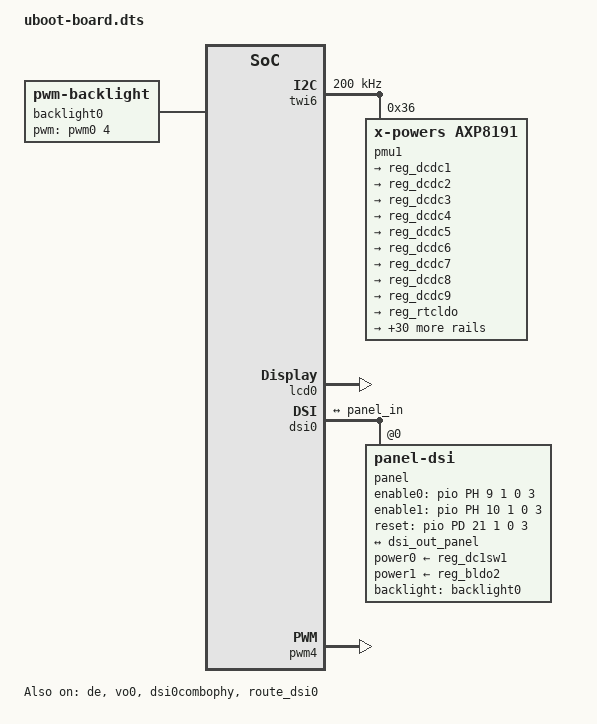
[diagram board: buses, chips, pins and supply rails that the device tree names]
/*
 * Allwinner Technology CO., Ltd. sun60iw2p1 soc board.
 *
 * soc board support.
 */

/ {
	backlight0: backlight0 {
		compatible = "pwm-backlight";
		status = "okay";
		brightness-levels = <
			  0   1   2   3   4   5   6   7
			  8   9  10  11  12  13  14  15
			 16  17  18  19  20  21  22  23
			 24  25  26  27  28  29  30  31
			 32  33  34  35  36  37  38  39
			 40  41  42  43  44  45  46  47
			 48  49  50  51  52  53  54  55
			 56  57  58  59  60  61  62  63
			 64  65  66  67  68  69  70  71
			 72  73  74  75  76  77  78  79
			 80  81  82  83  84  85  86  87
			 88  89  90  91  92  93  94  95
			 96  97  98  99 100 101 102 103
			104 105 106 107 108 109 110 111
			112 113 114 115 116 117 118 119
			120 121 122 123 124 125 126 127
			128 129 130 131 132 133 134 135
			136 137 138 139 140 141 142 143
			144 145 146 147 148 149 150 151
			152 153 154 155 156 157 158 159
			160 161 162 163 164 165 166 167
			168 169 170 171 172 173 174 175
			176 177 178 179 180 181 182 183
			184 185 186 187 188 189 190 191
			192 193 194 195 196 197 198 199
			200 201 202 203 204 205 206 207
			208 209 210 211 212 213 214 215
			216 217 218 219 220 221 222 223
			224 225 226 227 228 229 230 231
			232 233 234 235 236 237 238 239
			240 241 242 243 244 245 246 247
			248 249 250 251 252 253 254 255>;
		default-brightness-level = <73>;
		pwms = <&pwm0 4 25000 0>;
	};
};

&platform {
	eraseflag   = <1>;
	next_work   = <3>;
	debug_mode  = <4>;
};

&target {
	boot_clock = <1008>;	/*CPU boot frequency, Unit: MHz*/
	storage_type = <0xffffffff>; /*boot medium, 0-nand, 1-card0, 2-card2, -1(defualt)auto scan*/
	burn_key = <1>;		/*1:support burn key; 0:not support burn key*/
	dragonboard_test = <0>;	/*1:support card boot dragonboard; 0:not support card boot dragonboard*/
};

&power_sply {
	ntc_status = <0>;
};

&charger0 {
	pmu_safe_vol = <3400>;
	ntc_cur = <60>;
	safe_temp_H = <600>;//60
	safe_temp_L = <0xFFFFFFCE>;//-5
	pmu_bat_temp_para1 = <4541>; //Murata -25
	pmu_bat_temp_para2 = <2762>; //-15
	pmu_bat_temp_para3 = <2180>; //-10
	pmu_bat_temp_para4 = <1732>; //-5
	pmu_bat_temp_para5 = <1386>;//0
	pmu_bat_temp_para6 = <1117>; //5
	pmu_bat_temp_para7 = <905>; //10
	pmu_bat_temp_para8 = <606>; //20
	pmu_bat_temp_para9 = <414>; //30
	pmu_bat_temp_para10 = <290>; //40
	pmu_bat_temp_para11 = <244>; //45
	pmu_bat_temp_para12 = <205>; //50
	pmu_bat_temp_para13 = <176>; //55
	pmu_bat_temp_para14 = <150>; //60
	pmu_bat_temp_para15 = <111>; //70
	pmu_bat_temp_para16 = <83>; //80
};

&twi6 {
	clock-frequency = <200000>;
	pinctrl-0 = <&s_twi0_pins_a>;
	pinctrl-1 = <&s_twi0_pins_b>;
	twi-supply = <&reg_aldo3>;
	status = "okay";

	pmu1: pmu@36 {
		compatible = "x-powers,axp8191";
		reg = <0x36>;
		status = "okay";
		regulator0: regulators@0 {
			reg_dcdc1: dcdc1 {
				regulator-name = "axp8191-dcdc1";
			};
			reg_dcdc2: dcdc2 {
				regulator-name = "axp8191-dcdc2";
			};
			reg_dcdc3: dcdc3 {
				regulator-name = "axp8191-dcdc3";
			};
			reg_dcdc4: dcdc4 {
				regulator-name = "axp8191-dcdc4";
			};
			reg_dcdc5: dcdc5 {
				regulator-name = "axp8191-dcdc5";
			};
			reg_dcdc6: dcdc6 {
				regulator-name = "axp8191-dcdc6";
			};
			reg_dcdc7: dcdc7 {
				regulator-name = "axp8191-dcdc7";
			};
			reg_dcdc8: dcdc8 {
				regulator-name = "axp8191-dcdc8";
			};
			reg_dcdc9: dcdc9 {
				regulator-name = "axp8191-dcdc9";
			};
			reg_rtcldo: rtcldo {
				regulator-name = "axp8191-rtcldo";
			};
			reg_aldo1: aldo1 {
				regulator-name = "axp8191-aldo1";
			};
			reg_aldo2: aldo2 {
				regulator-name = "axp8191-aldo2";
			};
			reg_aldo3: aldo3 {
				regulator-name = "axp8191-aldo3";
			};
			reg_aldo4: aldo4 {
				regulator-name = "axp8191-aldo4";
			};
			reg_aldo5: aldo5 {
				regulator-name = "axp8191-aldo5";
			};
			reg_aldo6: aldo6 {
				regulator-name = "axp8191-aldo6";
			};
			reg_bldo1: bldo1 {
				regulator-name = "axp8191-bldo1";
			};
			reg_bldo2: bldo2 {
				regulator-name = "axp8191-bldo2";
			};
			reg_bldo3: bldo3 {
				regulator-name = "axp8191-bldo3";
			};
			reg_bldo4: bldo4 {
				regulator-name = "axp8191-bldo4";
			};
			reg_bldo5: bldo5 {
				regulator-name = "axp8191-bldo5";
			};
			reg_cldo1: cldo1 {
				regulator-name = "axp8191-cldo1";
			};
			reg_cldo2: cldo2 {
				regulator-name = "axp8191-cldo2";
			};
			reg_cldo3: cldo3 {
				regulator-name = "axp8191-cldo3";
			};
			reg_cldo4: cldo4 {
				regulator-name = "axp8191-cldo4";
			};
			reg_cldo5: cldo5 {
				regulator-name = "axp8191-cldo5";
			};
			reg_dldo1: dldo1 {
				regulator-name = "axp8191-dldo1";
			};
			reg_dldo2: dldo2 {
				regulator-name = "axp8191-dldo2";
			};
			reg_dldo3: dldo3 {
				regulator-name = "axp8191-dldo3";
			};
			reg_dldo4: dldo4 {
				regulator-name = "axp8191-dldo4";
			};
			reg_dldo5: dldo5 {
				regulator-name = "axp8191-dldo5";
			};
			reg_dldo6: dldo6 {
				regulator-name = "axp8191-dldo6";
			};
			reg_eldo1: eldo1 {
				regulator-name = "axp8191-eldo1";
			};
			reg_eldo2: eldo2 {
				regulator-name = "axp8191-eldo2";
			};
			reg_eldo3: eldo3 {
				regulator-name = "axp8191-eldo3";
			};
			reg_eldo4: eldo4 {
				regulator-name = "axp8191-eldo4";
			};
			reg_eldo5: eldo5 {
				regulator-name = "axp8191-eldo5";
			};
			reg_eldo6: eldo6 {
				regulator-name = "axp8191-eldo6";
			};
			reg_dc1sw1: dc1sw1 {
				regulator-name = "axp8191-dc1sw1";
				swin-supply = <&reg_dcdc1>;
			};
			reg_dc1sw2: dc1sw2 {
				regulator-name = "axp8191-dc1sw2";
				swin-supply = <&reg_dcdc1>;
			};
		};
	};
};

&sdc0_pins_a {
		allwinner,pins = "PF0", "PF1", "PF2",
				 "PF3", "PF4", "PF5";
		allwinner,function = "sdc0";
		allwinner,muxsel = <2>;
		allwinner,drive = <1>;
		allwinner,pull = <1>;
};

&sdc0_pins_b {
		allwinner,pins = "PF0", "PF1", "PF2",
				 "PF3", "PF4", "PF5";
		allwinner,function = "io_disabled";
		allwinner,muxsel = <7>;
		allwinner,drive = <0>;
		allwinner,pull = <1>;
};

&sdc0_pins_c {
		allwinner,pins = "PF0", "PF1", "PF2",
		  		 "PF3", "PF4", "PF5";
		allwinner,function = "uart0_jtag";
		allwinner,muxsel = <3>;
		allwinner,drive = <0>;
		allwinner,pull = <1>;
};


&sdc2_pins_a {
		allwinner,pins = "PC1", "PC5", "PC6",
				 "PC8", "PC9", "PC10", "PC11",
				 "PC13", "PC14", "PC15", "PC16";
		allwinner,function = "sdc2";
		allwinner,muxsel = <3>;
		allwinner,drive = <1>;
		allwinner,pull = <1>;
};

&sdc2_pins_b {
		allwinner,pins = "PC0", "PC1", "PC5", "PC6",
				 "PC8", "PC9", "PC10", "PC11",
				 "PC13", "PC14", "PC15", "PC16";
		allwinner,function = "io_disabled";
		allwinner,muxsel = <7>;
		allwinner,drive = <0>;
		allwinner,pull = <1>;
};

&sdc2_pins_c {
		allwinner,pins = "PC0";
		allwinner,function = "sdc2";
		allwinner,muxsel = <3>;
		allwinner,drive = <1>;
		allwinner,pull = <2>;
};

&pwm4_pin_active {
		allwinner,pins = "PD22";
		allwinner,function = "pwm0_4";
		allwinner,muxsel = <0x2>;
		allwinner,drive = <3>;
		allwinner,pull = <2>;
};

&pwm4_pin_sleep {
		allwinner,pins = "PD22";
		allwinner,function = "io_disabled";
		allwinner,muxsel = <0xf>;
		allwinner,drive = <3>;
		allwinner,pull = <2>;
};

&card0_boot_para {
		/* Avoid dtc compiling warnings. @TODO: Developer should modify this to the actual value */
		/* reg = <0x0 0x2 0x0 0x0>;  [> Avoid dtc compiling warnings. @TODO: Developer should modify this to the actual value <] */
	device_type = "card0_boot_para";
	card_ctrl = <0x0>;
	card_high_speed = <0x1>;
	card_line = <0x4>;
	clk_mmc = "sdmmc0_mod";
	pll-0 = "hosc";
	pll-1 = "pll_periph1_400m";
	pll-2 = "pll_periph1_300m";
	pinctrl-0 = <&sdc0_pins_a>;
	clk_type = "typ1";
};

&card2_boot_para {
	/*
	* Avoid dtc compiling warnings.
	* @TODO: Developer should modify this to the actual value
	*/
	reg = <0x0 0x3 0x0 0x0>;
	device_type = "card2_boot_para";
	card_ctrl = <0x2>;
	card_high_speed = <0x1>;
	card_line = <0x8>;
	clk_mmc = "sdmmc2_mod";
	pll-0 = "hosc";
	pll-1 = "pll_periph1_800m";
	pll-2 = "pll_periph1_600m";
	pinctrl-0 = <&sdc2_pins_a &sdc2_pins_c>;
	sdc_ex_dly_used = <0x2>;
	sdc_tm4_hs200_max_freq = <150>;
	sdc_tm4_hs400_max_freq = <150>;
	sdc_tm4_win_th = <0x7>;
	sdc_io_1v8 = <0x1>;
	sdc_type = "tm4";
	clk_type = "typ1";
};

&key_boot_recovery {
	device_type = "key_boot_recovery";
	recovery_key_used = <0x1>;
	press_mode_enable = <0x0>;
	key_work_mode = <0x2>;
	short_press_mode = <0x0>;
	long_press_mode = <0x1>;
	key_press_time = <0x7d0>;
	recovery_key = <&pio PB 1 0x0 0xffffffff 0xffffffff 0x1>;//vol+
};

&de {
	chn_cfg_mode = <0>;
	status = "okay";
};

&vo0 {
	status = "okay";
};

&lcd0 {
	status = "okay";
};

&dsi0 {
	status = "okay";
	pinctrl-0 = <&dsi0_4lane_pins_a>;
	pinctrl-1 = <&dsi0_4lane_pins_b>;
	pinctrl-names = "active","sleep";
	ports {
		dsi1_out: port@1{
			dsi_out_panel: endpoint {
				remote-endpoint = <&panel_in>;
			};
		};
        };
	panel: panel@0 {
		compatible = "panel-dsi";
		status = "okay";
		reg = <0>;
		power-delay-ms = <10>;
		power0-supply = <&reg_dc1sw1>;
		power1-supply = <&reg_bldo2>;

		enable0-gpios = <&pio PH 9 1 0 3 1>;
		enable1-gpios = <&pio PH 10 1 0 3 1>;
		reset-num = <2>;
		reset-delay-ms = <20>;
		reset-gpios = <&pio PD 21 1 0 3 1>;
		backlight = <&backlight0>;
		dsi,flags = <MIPI_DSI_MODE_VIDEO>;
		dsi,lanes = <4>;
		dsi,format = <0>;
		panel-init-sequence = [
			15 00 02 00 00
			15 00 02 FA 5A
			15 00 02 00 00
			39 00 04 FF 82 05 01
			15 00 02 00 80
			39 00 03 FF 82 05
			15 00 02 00 93
			15 00 02 C5 6B
			15 00 02 00 97
			15 00 02 C5 6B
			15 00 02 00 9E
			15 00 02 C5 0A
			15 00 02 00 9A
			15 00 02 C5 CD
			15 00 02 00 9C
			15 00 02 C5 CD
			15 00 02 00 B6
			39 00 03 C5 57 57
			15 00 02 00 B8
			39 00 03 C5 43 43
			15 00 02 00 A0
			15 00 02 A5 04
			15 00 02 00 00
			39 00 03 D8 B4 B4
			15 00 02 00 82
			15 00 02 C5 95
			15 00 02 00 83
			15 00 02 C5 07
			15 00 02 00 D9
			15 00 02 CB 40
			15 00 02 00 00
			39 00 11 E1 00 04 11 1E 27 31 41 4F 52 5F 63 79 88 73 71 65
			15 00 02 00 10
			39 00 09 E1 5B 4F 3E 34 2B 1E 16 15
			15 00 02 00 00
			39 00 11 E2  00 04 11 1E 27 31 41 4F 52 5F 63 79 88 73 71 65
			15 00 02 00 10
			39 00 09 E2 5B 4F 3E 34 2B 1B 0C 0A
			15 00 02 00 A1
			39 00 03 B3 04 B0
			15 00 02 00 A3
			39 00 03 B3 07 D0
			15 00 02 00 A5
			39 00 03 B3 80 13
			15 00 02 00 80
			39 00 08 CB 3C 3C 3C 3C 3C 3C 3C
			15 00 02 00 87
			15 00 02 CB 3C
			15 00 02 00 88
			39 00 09 CB 3C 3C 3C 3C 3C 3C 3C 3C
			15 00 02 00 90
			39 00 07 CB 03 3C 3C 3C 3C 3C
			15 00 02 00 97
			15 00 02 CB 33
			15 00 02 00 98
			39 00 09 CB 34 34 34 34 34 34 34 34
			15 00 02 00 A0
			39 00 09 CB 34 34 34 37 34 34 34 34
			15 00 02 00 A8
			39 00 07 CB C8 34 34 34 34 34
			15 00 02 00 B0
			39 00 08 CB 00 00 00 00 00 00 00
			15 00 02 00 B7
			15 00 02 CB 00
			15 00 02 00 B8
			39 00 09 CB 00 00 00 00 00 00 00 00
			15 00 02 00 C0
			39 00 08 CB 00 00 00 00 00 00 00
			15 00 02 00 C7
			15 00 02 CB 00
			15 00 02 00 80
			39 00 09 CC 2F 2F 2F 27 31 32 01 2C
			15 00 02 00 88
			39 00 09 CC 2D 1B 1D 1F 21 0B 0D 0F
			15 00 02 00 90
			39 00 07 CC 11 13 15 03 2F 2F
			15 00 02 00 80
			39 00 09 CD 2F 2F 2F 27 31 32 02 2C
			15 00 02 00 88
			39 00 09 CD 2D 1C 1E 20 22 0C 0E 10
			15 00 02 00 90
			39 00 07 CD 12 14 16 04 2F 2F
			15 00 02 00 80
			39 00 05 C2 8C 0A 7A AA
			15 00 02 00 84
			39 00 05 C2 8B 0A 7A AA
			15 00 02 00 C0
			39 00 08 C2 86 87 00 06 7A AA 0B
			15 00 02 00 C7
			39 00 08 C2 85 86 00 06 7A AA 0B
			15 00 02 00 D0
			39 00 08 C2 84 85 00 06 7A AA 0B
			15 00 02 00 D7
			39 00 08 C2 83 84 00 06 7A AA 0B
			15 00 02 00 E0
			39 00 08 C2 82 83 00 06 7A AA 0B
			15 00 02 00 E7
			39 00 08 C2 81 82 00 06 7A AA 0B
			15 00 02 00 F0
			39 00 08 C2 80 81 00 06 7A AA 0B
			15 00 02 00 F7
			39 00 08 C2 01 80 00 06 7A AA 0B
			15 00 02 00 80
			39 00 08 C3 02 8B 00 06 7A AA 0B
			15 00 02 00 87
			39 00 08 C3 03 8A 00 06 7A AA 0B
			15 00 02 00 90
			39 00 08 C3 04 89 00 06 7A AA 0B
			15 00 02 00 97
			39 00 08 C3 05 88 00 06 7A AA 0B
			15 00 02 00 A0
			39 00 05 C2 06 46 7A AA
			15 00 02 00 A4
			39 00 05 C2 05 46 7A AA
			15 00 02 00 A8
			39 00 05 C2 04 46 7A AA
			15 00 02 00 AC
			39 00 05 C2 03 46 7A AA
			15 00 02 00 B0
			39 00 05 C2 02 46 7A AA
			15 00 02 00 B4
			39 00 05 C2 01 46 7A AA
			15 00 02 00 B8
			39 00 05 C2 00 06 7A AA
			15 00 02 00 BC
			39 00 05 C2 01 06 7A AA
			15 00 02 00 A0
			39 00 09 C3 00 70 D3 0A 7A AA 00 00
			15 00 02 00 A8
			39 00 09 C3 00 70 D4 0B 7A AA 00 00
			15 00 02 00 F0
			39 00 06 CC 3D 8E 8E 18 18
			15 00 02 00 A2
			15 00 02 F3 55
			15 00 02 00 E0
			39 00 05 C3 27 00 00 00
			15 00 02 00 E4
			39 00 05 C3 27 00 00 00
			15 00 02 00 EC
			39 00 03 C3 C2 C2
			15 00 02 00 E8
			39 00 05 C3 44 00 0C 70
			15 00 02 00 EE
			15 00 02 C3 02
			15 00 02 00 80
			39 00 07 C0 00 8C 00 DC 00 10
			15 00 02 00 90
			39 00 07 C0 00 8C 00 DC 00 10
			15 00 02 00 A0
			39 00 07 C0 00 F0 00 DC 00 10
			15 00 02 00 B0
			39 00 06 C0 00 A7 00 DC 10
			15 00 02 00 A3
			39 00 07 C1 00 24 00 24 00 04
			15 00 02 00 80
			39 00 0D CE 01 81 0B 21 00 35 00 AC 00 2A 00 3A
			15 00 02 00 90
			39 00 0F CE 00 88 0C 66 00 88 80 0B 21 00 03 00 1C 0C
			15 00 02 00 A0
			39 00 04 CE 10 00 00
			15 00 02 00 B0
			39 00 04 CE 62 00 00
			15 00 02 00 CC
			39 00 03 CE 07 F8
			15 00 02 00 D0
			39 00 09 CE 01 00 0F 01 01 00 DE 01
			15 00 02 00 E1
			39 00 08 CE 0A 01 6B 02 37 00 82
			15 00 02 00 F0
			39 00 0B CE 00 11 08 01 2D 01 D6 00 EC 1A
			15 00 02 00 B0
			39 00 05 CF 07 07 DA DE
			15 00 02 00 B5
			39 00 05 CF 03 03 A6 AA
			15 00 02 00 C0
			39 00 05 CF 07 07 DA DE
			15 00 02 00 C5
			39 00 05 CF 00 07 1C D0
			15 00 02 00 90
			15 00 02 C1 22
			15 00 02 00 9C
			15 00 02 C1 08
			15 00 02 00 00
			15 00 02 35 01
			15 00 02 00 9F
			15 00 02 C5 00
			15 00 02 00 98
			15 00 02 C5 54
			15 00 02 00 91
			15 00 02 C5 4C
			15 00 02 00 8C
			39 00 03 CF 40 40
			15 00 02 00 93
			15 00 02 C4 90
			15 00 02 00 D7
			15 00 02 C0 F0
			15 00 02 00 A2
			15 00 02 F5 1F
			15 00 02 00 90
			15 00 02 E9 10
			15 00 02 00 B1
			15 00 02 F5 02
			15 00 02 00 80
			15 00 02 A4 2C
			15 00 02 00 84
			15 00 02 C5 FD
			15 00 02 00 88
			15 00 02 B0 07
			15 00 02 00 00
			15 00 02 FA 01
			15 00 02 00 A8
			15 00 02 C5 99
			15 00 02 00 B6
			39 00 03 C5 55 55
			15 00 02 00 B8
			39 00 03 C5 41 41
			15 00 02 00 9A
			15 00 02 F5 00
			15 00 02 00 B2
			15 00 02 CE 92
			15 00 02 00 00
			15 00 02 FA 5A
			15 00 02 00 88
			15 00 02 B0 01
			15 00 02 00 00
			39 00 04 FF 00 00 00
			15 00 02 00 80
			39 00 03 FF 00 00
			15 96 02 11 00
			15 32 02 29 00
			15 00 02 35 00
		];

		panel-exit-sequence = [
			05 00 01 28
			05 78 01 10
		];

		display-timings {
			native-mode = <&timing0>;
			timing0: timing0 {
				clock-frequency = <171993120>;
				hback-porch = <26>;
				hactive = <1200>;
				hfront-porch = <46>;
				hsync-len = <10>;
				vback-porch = <20>;
				vactive = <2000>;
				vfront-porch = <212>;
				vsync-len = <4>;
			};
		};
		port {
			panel_in: endpoint {
                                remote-endpoint = <&dsi_out_panel>;
                        };
		};
	};
};

&dsi0combophy {
	status = "okay";
};

&route_dsi0 {
	status = "okay";
	logo,uboot = "bootlogo.bmp";
};

&pwm4{
	pinctrl-names = "active","sleep";
	pinctrl-0 = <&pwm4_pin_active>;
	pinctrl-1 = <&pwm4_pin_sleep>;
	status = "okay";
};

